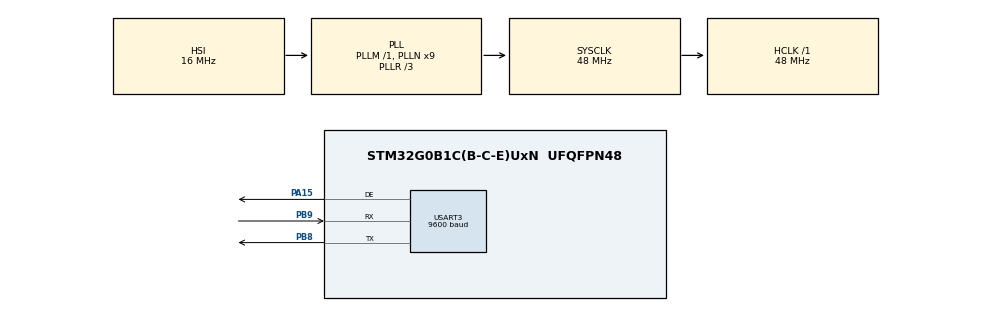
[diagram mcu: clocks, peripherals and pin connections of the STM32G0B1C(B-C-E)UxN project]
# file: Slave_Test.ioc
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Mcu.Family=STM32G0
Mcu.Name=STM32G0B1C(B-C-E)UxN
Mcu.Package=UFQFPN48
NVIC.TIM14_IRQn=true\:0\:0\:false\:false\:true\:true\:true\:true
NVIC.TIM16_FDCAN_IT0_IRQn=true\:0\:0\:false\:false\:true\:true\:true\:true
NVIC.USART3_4_5_6_LPUART1_IRQn=true\:0\:0\:false\:false\:true\:true\:true\:true
PA15.Mode=Hardware Flow Control (RS485)
PA15.Signal=USART3_DE
PB8.Mode=Asynchronous
PB8.Signal=USART3_TX
PB9.Mode=Asynchronous
PB9.Signal=USART3_RX
ProjectManager.HeapSize=0x200
ProjectManager.StackSize=0x400
ProjectManager.TargetToolchain=STM32CubeIDE
RCC.ADCFreq_Value=48000000
RCC.AHBFreq_Value=48000000
RCC.CortexFreq_Value=48000000
RCC.EXTERNAL_CLOCK_VALUE=48000
RCC.HCLKFreq_Value=48000000
RCC.HSE_VALUE=8000000
RCC.HSI48_VALUE=48000000
RCC.HSI_VALUE=16000000
RCC.LSE_VALUE=32768
RCC.PLLN=9
RCC.PLLR=RCC_PLLR_DIV3
RCC.SYSCLKFreq_VALUE=48000000
RCC.SYSCLKSource=RCC_SYSCLKSOURCE_PLLCLK
RCC.USBFreq_Value=48000000
RCC.VCOOutputFreq_Value=144000000
TIM14.Period=0
TIM14.Prescaler=2399
TIM16.Period=1999
TIM16.Prescaler=47
USART3.BaudRate=9600
USART3.VirtualMode-Asynchronous=VM_ASYNC
USART3.VirtualMode-Hardware\ Flow\ Control\ (RS485)=VM_ASYNC
VP_SYS_VS_DBSignals.Mode=DisableDeadBatterySignals
VP_TIM14_VS_ClockSourceINT.Mode=Enable_Timer
VP_TIM16_VS_ClockSourceINT.Mode=Enable_Timer
board=custom

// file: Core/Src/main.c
/* USER CODE BEGIN Header */
/**
  ******************************************************************************
  * @file           : main.c
  * @brief          : Main program body
  ******************************************************************************
  * @attention
  *
  * Copyright (c) 2025 STMicroelectronics.
  * All rights reserved.
  *
  * This software is licensed under terms that can be found in the LICENSE file
  * in the root directory of this software component.
  * If no LICENSE file comes with this software, it is provided AS-IS.
  *
  ******************************************************************************
  */
/* USER CODE END Header */
#include "main.h"
#include "tim.h"
#include "usart.h"
#include "gpio.h"

/* USER CODE BEGIN Includes */
#include "mb_slave_API.h"
#include "mb.h"
#include "mb_API.h"
#include "port.h"
#include "mb_slave_API.h"
/* USER CODE END Includes */

void SystemClock_Config(void);

/* USER CODE BEGIN 0 */
uint16_t qq[10]={0x44,0x66,0x77,0x45 ,0xFF ,0x4A ,0x11,0x22} ;
uint16_t ss[10];
/* USER CODE END 0 */

int main(void)
{

  /* MCU Configuration--------------------------------------------------------*/

  /* Reset of all peripherals, Initializes the Flash interface and the Systick. */
  HAL_Init();

  /* Configure the system clock */
  SystemClock_Config();

  /* Initialize all configured peripherals */
  MX_GPIO_Init();
  MX_TIM14_Init();
  MX_USART3_UART_Init();
  MX_TIM16_Init();
  /* USER CODE BEGIN 2 */
	MbSlaveMode(MB_RTU, MB_SLAVE_ADDRESS, PORT, BAUD_RATE, MB_PAR_NONE);
  /* USER CODE END 2 */

  /* Infinite loop */
  /* USER CODE BEGIN WHILE */
	while (1) {
			  WriteToModbusBuffer(qq, 0, 8);
//		ReadFromModbusBuffer(ss, 0, 10);
    /* USER CODE END WHILE */

	}
}

void SystemClock_Config(void)
{
  RCC_OscInitTypeDef RCC_OscInitStruct = {0};
  RCC_ClkInitTypeDef RCC_ClkInitStruct = {0};

  /** Configure the main internal regulator output voltage
  */
  HAL_PWREx_ControlVoltageScaling(PWR_REGULATOR_VOLTAGE_SCALE1);

  /** Initializes the RCC Oscillators according to the specified parameters
  * in the RCC_OscInitTypeDef structure.
  */
  RCC_OscInitStruct.OscillatorType = RCC_OSCILLATORTYPE_HSI;
  RCC_OscInitStruct.HSIState = RCC_HSI_ON;
  RCC_OscInitStruct.HSIDiv = RCC_HSI_DIV1;
  RCC_OscInitStruct.HSICalibrationValue = RCC_HSICALIBRATION_DEFAULT;
  RCC_OscInitStruct.PLL.PLLState = RCC_PLL_ON;
  RCC_OscInitStruct.PLL.PLLSource = RCC_PLLSOURCE_HSI;
  RCC_OscInitStruct.PLL.PLLM = RCC_PLLM_DIV1;
  RCC_OscInitStruct.PLL.PLLN = 9;
  RCC_OscInitStruct.PLL.PLLP = RCC_PLLP_DIV2;
  RCC_OscInitStruct.PLL.PLLQ = RCC_PLLQ_DIV2;
  RCC_OscInitStruct.PLL.PLLR = RCC_PLLR_DIV3;
  if (HAL_RCC_OscConfig(&RCC_OscInitStruct) != HAL_OK)
  {
    Error_Handler();
  }

  /** Initializes the CPU, AHB and APB buses clocks
  */
  RCC_ClkInitStruct.ClockType = RCC_CLOCKTYPE_HCLK|RCC_CLOCKTYPE_SYSCLK
                              |RCC_CLOCKTYPE_PCLK1;
  RCC_ClkInitStruct.SYSCLKSource = RCC_SYSCLKSOURCE_PLLCLK;
  RCC_ClkInitStruct.AHBCLKDivider = RCC_SYSCLK_DIV1;
  RCC_ClkInitStruct.APB1CLKDivider = RCC_HCLK_DIV1;

  if (HAL_RCC_ClockConfig(&RCC_ClkInitStruct, FLASH_LATENCY_1) != HAL_OK)
  {
    Error_Handler();
  }
}

void Error_Handler(void)
{
  __disable_irq();
  while (1)
  {
  }
}
